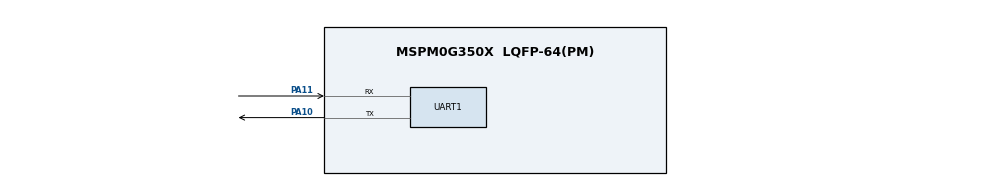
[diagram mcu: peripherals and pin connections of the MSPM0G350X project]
/**
 * @cliArgs --device "MSPM0G350X" --package "LQFP-64(PM)" --part "Default" --product "mspm0_sdk@1.20.01.06"
 * @versions {"tool":"1.18.0+3266"}
 */

/**
 * Import the modules used in this configuration.
 */
const COMP   = scripting.addModule("/ti/driverlib/COMP", {}, false);
const COMP1  = COMP.addInstance();
const GPIO   = scripting.addModule("/ti/driverlib/GPIO", {}, false);
const GPIO1  = GPIO.addInstance();
const SYSCTL = scripting.addModule("/ti/driverlib/SYSCTL");
const UART   = scripting.addModule("/ti/driverlib/UART", {}, false);
const UART1  = UART.addInstance();

/**
 * Write custom configuration values to the imported modules.
 */
COMP1.$name                          = "COMP_0";
COMP1.channelEnable                  = ["NEG"];
COMP1.polarity                       = "DL_COMP_POLARITY_INV";
COMP1.outputEnable                   = true;
COMP1.enableOutputFilter             = true;
COMP1.selectOutputFilter             = "DL_COMP_FILTER_DELAY_1200";
COMP1.hysteresis                     = "DL_COMP_HYSTERESIS_30";
COMP1.vSource                        = "DL_COMP_REF_SOURCE_VDDA_DAC";
COMP1.controlSelect                  = "DL_COMP_DAC_CONTROL_SW";
COMP1.peripheral.$assign             = "COMP0";
COMP1.peripheral.compPinNeg0.$assign = "PA27";
COMP1.peripheral.compPinOut.$assign  = "PA7";
COMP1.compPinNeg0Config.$name        = "ti_driverlib_gpio_GPIOPinGeneric2";
COMP1.compPinOutConfig.$name         = "ti_driverlib_gpio_GPIOPinGeneric3";

const Board = scripting.addModule("/ti/driverlib/Board", {}, false);

GPIO1.port                           = "PORTA";
GPIO1.$name                          = "GPIO_LEDS";
GPIO1.associatedPins[0].assignedPin  = "0";
GPIO1.associatedPins[0].initialValue = "SET";
GPIO1.associatedPins[0].$name        = "USER_LED_1";

SYSCTL.forceDefaultClkConfig = true;
SYSCTL.clockTreeEn           = true;

UART1.$name                    = "UART_0";
UART1.targetBaudRate           = 115200;
UART1.uartClkDiv               = "4";
UART1.enabledInterrupts        = ["RX"];
UART1.peripheral.$assign       = "UART0";
UART1.peripheral.rxPin.$assign = "PA11";
UART1.peripheral.txPin.$assign = "PA10";
UART1.txPinConfig.$name        = "ti_driverlib_gpio_GPIOPinGeneric0";
UART1.rxPinConfig.$name        = "ti_driverlib_gpio_GPIOPinGeneric1";

/**
 * Pinmux solution for unlocked pins/peripherals. This ensures that minor changes to the automatic solver in a future
 * version of the tool will not impact the pinmux you originally saw.  These lines can be completely deleted in order to
 * re-solve from scratch.
 */
Board.peripheral.$suggestSolution            = "DEBUGSS";
Board.peripheral.swclkPin.$suggestSolution   = "PA20";
Board.peripheral.swdioPin.$suggestSolution   = "PA19";
GPIO1.associatedPins[0].pin.$suggestSolution = "PA0";
